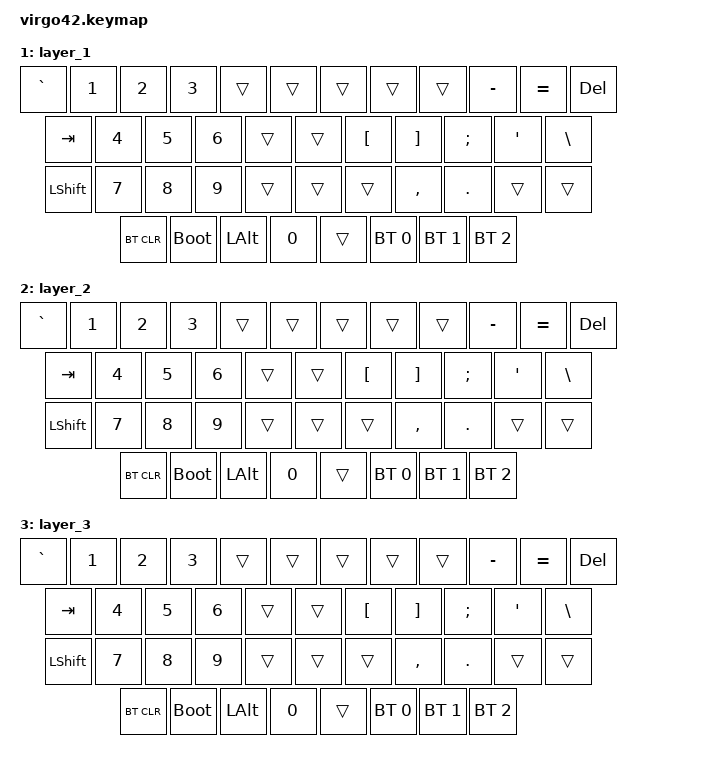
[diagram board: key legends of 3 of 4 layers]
/*
 * Copyright (c) 2020 The ZMK Contributors
 *
 * SPDX-License-Identifier: MIT
 */

#include <behaviors.dtsi>
#include <dt-bindings/zmk/bt.h>
#include <dt-bindings/zmk/keys.h>
#include <dt-bindings/zmk/outputs.h>
#include <dt-bindings/zmk/rgb.h>
#include <dt-bindings/zmk/ext_power.h>

/ {
    keymap0: keymap {
        compatible = "zmk,keymap";

        layer_0 {
            bindings = <
    &kp ESC  &kp Q  &kp W  &kp E  &kp R  &kp T  &kp Y  &kp U  &kp I  &kp O  &kp P  &kp BSPC 
	&kp CLCK  &kp A  &kp S  &kp D  &kp F  &kp G  &kp H  &kp J  &kp K  &kp L    &kp RET       
	&kp LSHFT   &kp Z  &kp X  &kp C  &kp V  &kp B  &kp N  &kp M  &kp FSLH  &kp UP  &mo 1   
	&kp LCTRL  &kp LGUI  &kp LALT  &kp SPACE      &kp SPACE     &kp LEFT  &kp DOWN  &kp RIGHT  T
            >;
        };

        layer_1 {
            bindings = <
    &kp GRAVE   &kp N1   &kp N2   &kp N3   &trans   &trans   &trans   &trans   &trans   &kp MINUS   &kp EQUAL   &kp DEL
	&kp TAB      &kp N4   &kp N5   &kp N6   &trans   &trans   &kp LBKT   &kp RBKT   &kp SEMI   &kp SQT   &kp BSLH
	&kp LSHFT       &kp N7   &kp N8   &kp N9   &trans   &trans   &trans   &kp COMMA   &kp DOT   &trans     &trans
	&bt BT_CLR   &bootloader   &kp LALT        &kp N0          &trans         &bt BT_SEL 0   &bt BT_SEL 1   &bt BT_SEL 2
            >;
        };

        layer_2 {
            bindings = <
    &kp GRAVE   &kp N1   &kp N2   &kp N3   &trans   &trans   &trans   &trans   &trans   &kp MINUS   &kp EQUAL   &kp DEL
	&kp TAB      &kp N4   &kp N5   &kp N6   &trans   &trans   &kp LBKT   &kp RBKT   &kp SEMI   &kp SQT   &kp BSLH
	&kp LSHFT       &kp N7   &kp N8   &kp N9   &trans   &trans   &trans   &kp COMMA   &kp DOT   &trans     &trans
	&bt BT_CLR   &bootloader   &kp LALT        &kp N0          &trans         &bt BT_SEL 0   &bt BT_SEL 1   &bt BT_SEL 2
            >;
        };

        layer_3 {
            bindings = <
    &kp GRAVE   &kp N1   &kp N2   &kp N3   &trans   &trans   &trans   &trans   &trans   &kp MINUS   &kp EQUAL   &kp DEL
	&kp TAB      &kp N4   &kp N5   &kp N6   &trans   &trans   &kp LBKT   &kp RBKT   &kp SEMI   &kp SQT   &kp BSLH
	&kp LSHFT       &kp N7   &kp N8   &kp N9   &trans   &trans   &trans   &kp COMMA   &kp DOT   &trans     &trans
	&bt BT_CLR   &bootloader   &kp LALT        &kp N0          &trans         &bt BT_SEL 0   &bt BT_SEL 1   &bt BT_SEL 2
            >;
        };
    };
};
